# rCSL_dspintc_001 register map
Vendor: Texas Instruments
Peripheral module from a debugger description file (folder c674x).
Registers are 32-bit, access not given, reset 0x0 unless marked. A register's access mark holds for its fields unless they carry their own. Offsets are as the file gives them; lines under a group give offsets from that group; [hi:lo] are bit positions; {n}, {i} and the like mark numbered series; 'fields as' and 'values as' point back to an identical list; <NAME> marks a mode.

## INTC — Interrupt
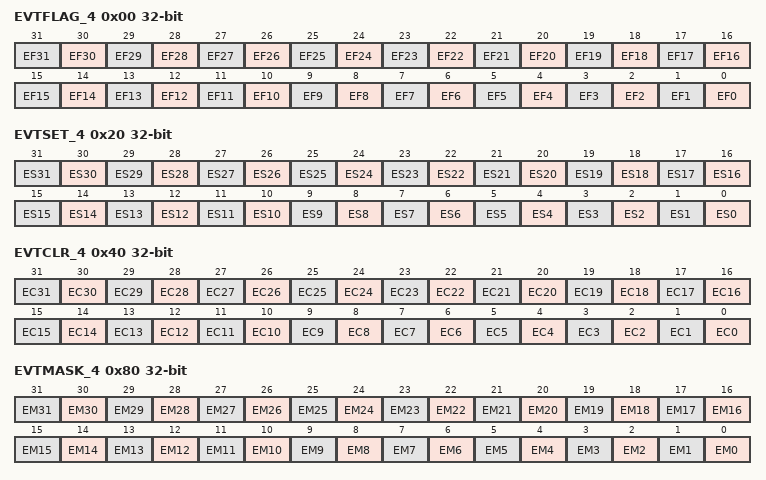
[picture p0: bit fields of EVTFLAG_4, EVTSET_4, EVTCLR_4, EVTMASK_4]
0x00 EVTFLAG_4 ro — Event Flag 0-3 Register - Events Status 0-31
  [n] EF{n} (n=0..31) — Event Flag number {n}
0x20 EVTSET_4 wo — Event Set 0-3 Register - Used to Sets Events 0-127
  [n] ES{n} (n=0..31) — Event Set number {n}
0x40 EVTCLR_4 wo — Event Clr 0-3 Register - Used to Clear Events 0-127
  [n] EC{n} (n=0..31) — Event Clear {n}
0x80 EVTMASK_4 rw — Event Mask 0-3 Register - Used to Mask Events 0-127
  [n] EM{n} (n=0..31) — Event Mask {n}
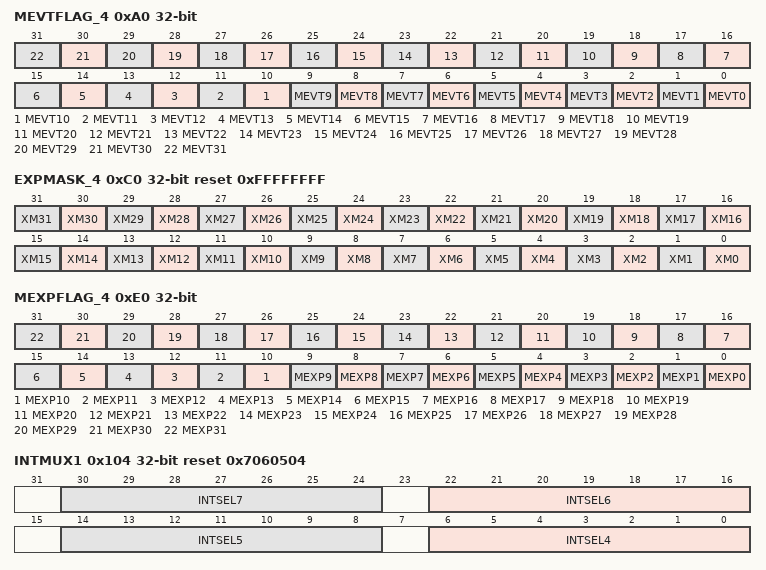
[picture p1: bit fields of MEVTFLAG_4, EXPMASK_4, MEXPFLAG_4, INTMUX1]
0xA0 MEVTFLAG_4 ro — Event Mask Flag 0-3 Register - Status Flags of Masked Events 0-127
  [n] MEVT{n} (n=0..31) — Masked Event Status {n}
0xC0 EXPMASK_4 rw reset 0xFFFFFFFF — Exception Mask 0-3 Register - Mask to generate EXCEP upon Events 0-127
  [n] XM{n} (n=0..31) — Exception Mask {n}
0xE0 MEXPFLAG_4 ro — Masked Exceptions Flag 1 Register - Status Flags of Masked Exception Events 32-63
  [n] MEXP{n} (n=0..31) — Masked Event Flag {n}
0x104 INTMUX1 reset 0x7060504 — Interrupt Multiplexer Register 1
  [8n-26:8n-32] INTSEL{n} rw (n=4..7) — Interrupt Selector {n}
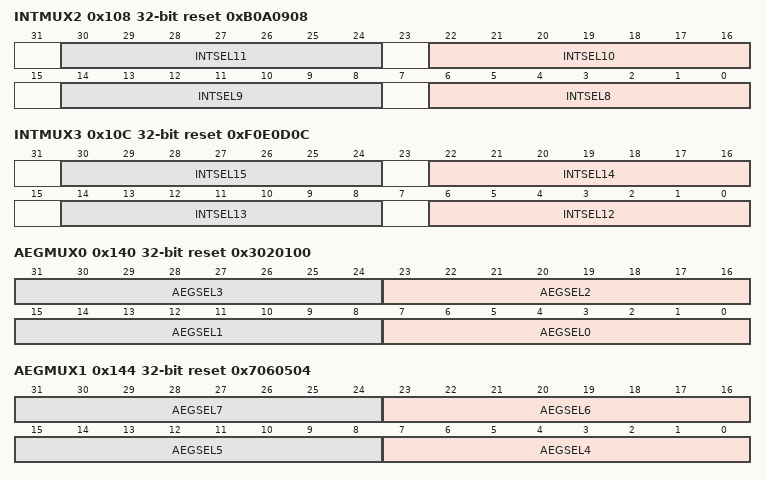
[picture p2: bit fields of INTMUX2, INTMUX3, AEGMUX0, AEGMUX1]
0x108 INTMUX2 reset 0xB0A0908 — Interrupt Multiplexer Register 2
  [8n-58:8n-64] INTSEL{n} rw (n=8..11) — Interrupt Selector {n}
0x10C INTMUX3 reset 0xF0E0D0C — Interrupt Multiplexer Register 3
  [8n-90:8n-96] INTSEL{n} rw (n=12..15) — Interrupt Selector {n}
0x140 AEGMUX0 rw reset 0x3020100 — Advanced Event Generator MUX Register 0
  [8n+7:8n] AEGSEL{n} (n=0..3) — AEG Event Selector {n}
0x144 AEGMUX1 rw reset 0x7060504 — Advanced Event Generator MUX Register 1
  [8n-25:8n-32] AEGSEL{n} (n=4..7) — AEG Event Selector {n}
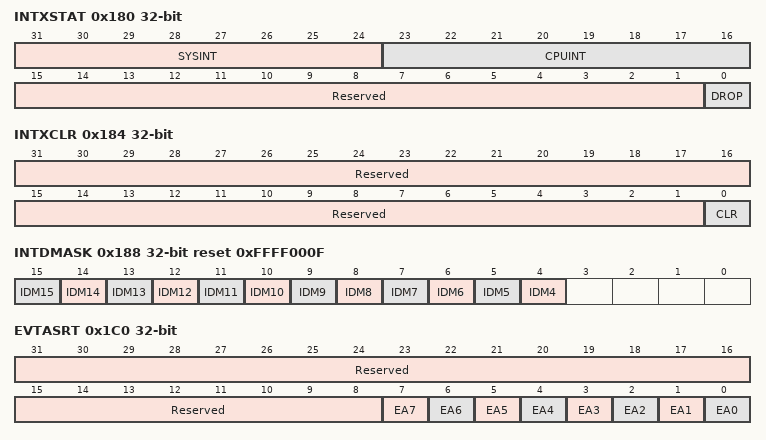
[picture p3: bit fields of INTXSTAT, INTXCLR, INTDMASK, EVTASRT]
0x180 INTXSTAT — Interrupt Exception Status Register - Holds ID of CPU Int and System Even number of the dropped Event
  [31:24] SYSINT ro — System Event Number
  [23:16] CPUINT ro — CPU Interrupt Number for Exception
    {v}=NUM{v} (CPU Interrupt Number {v}) (v=0..9); {v}=NUM{v-6} (CPU Interrupt Number {v-6}) (v=16..21)
  [15:1] Reserved — (access N)
  [0] DROP ro — Dropped Event Flag
    0=NO (No Events Dropped); 1=YES (Event was dropped by the CPU)
0x184 INTXCLR — Interrupt Exception Clear Register - Clears Interrupt Exception Status Register
  [31:1] Reserved — (access N)
  [0] CLR wo — Interrupt Exception Clear Field
0x188 INTDMASK reset 0xFFFF000F — Dropped Interrupt Mask Register
  [n] IDM{n} rw (n=4..15) — Interrupt Drop Mask {n}
0x1C0 EVTASRT — Event Pulse Generation Assertion Register - Used to Puse EVTPULSE(7:0) as an event between CPUs
  [31:8] Reserved — (access N)
  [n] EA{n} wo (n=0..7) — Event Assertion {n}
    1=SET (Assert Event)
